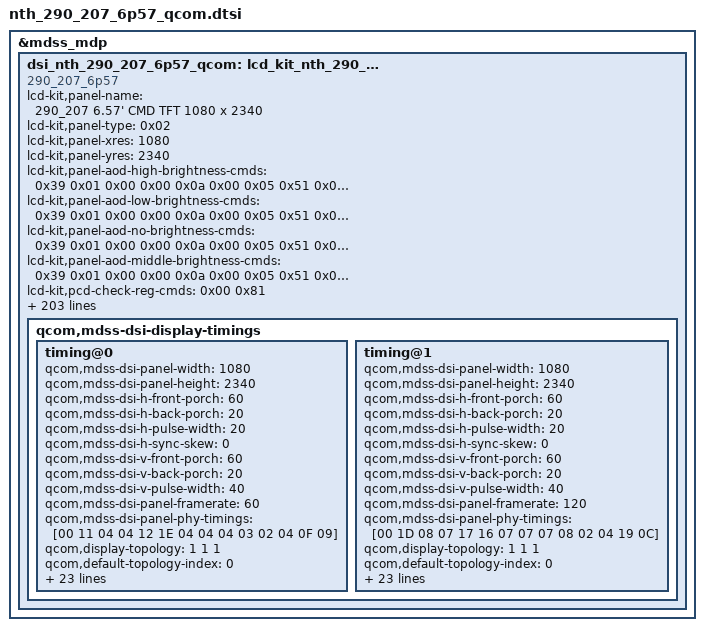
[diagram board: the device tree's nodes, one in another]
/* Copyright (c) 2013, The Linux Foundation. All rights reserved.
 *
 * This program is free software; you can redistribute it and/or modify
 * it under the terms of the GNU General Public License version 2 and
 * only version 2 as published by the Free Software Foundation.
 *
 * This program is distributed in the hope that it will be useful,
 * but WITHOUT ANY WARRANTY; without even the implied warranty of
 * MERCHANTABILITY or FITNESS FOR A PARTICULAR PURPOSE.  See the
 * GNU General Public License for more details.
 */

/*-------------------------------------------------------------------------
 * This file is autogenerated file using gcdb parser. Please do not edit it.
 * Update input XML file to add a new entry or update variable in this file
 * VERSION = 1.1
 *-----------------------------------------------------------------------*/
&mdss_mdp {
	dsi_nth_290_207_6p57_qcom: lcd_kit_nth_290_207_6p57_qcom {
		compatible = "290_207_6p57";
		lcd-kit,panel-name = "290_207 6.57' CMD TFT 1080 x 2340";
		lcd-kit,panel-type = <0x02>;
		lcd-kit,panel-xres = <1080>;
		lcd-kit,panel-yres = <2340>;
		lcd-kit,panel-aod-high-brightness-cmds = <0x39 0x01 0x00 0x00 0x0a 0x00 0x05 0x51 0x00 0x00 0x0F 0xFF>;
		lcd-kit,panel-aod-low-brightness-cmds = <0x39 0x01 0x00 0x00 0x0a 0x00 0x05 0x51 0x00 0x00 0x01 0x55>;
		lcd-kit,panel-aod-no-brightness-cmds = <0x39 0x01 0x00 0x00 0x0a 0x00 0x05 0x51 0x00 0x00 0x00 0x00>;
		lcd-kit,panel-aod-middle-brightness-cmds = <0x39 0x01 0x00 0x00 0x0a 0x00 0x05 0x51 0x00 0x00 0x07 0xFF>;
		lcd-kit,pcd-check-reg-cmds = <0x00 0x81>;
		lcd-kit,check-reg-on-cmds = <0x06 0x01 0x00 0x00 0x0a 0x00 0x01 0x0a>;
		lcd-kit,check-reg-on-value = <0x9c>;
		lcd-kit,check-aod-reg-on-cmds = <0x06 0x01 0x00 0x00 0x0a 0x00 0x01 0x0a>;
		lcd-kit,check-aod-reg-on-value = <0xdc>;
		lcd-kit,check-reg-off-cmds = <0x06 0x01 0x00 0x00 0x0a 0x00 0x01 0x0a>;
		lcd-kit,check-reg-off-value = <0x08>;
		lcd-kit,check-reg-on-cmds-state = "dsi_lp_mode";
		lcd-kit,check-aod-reg-on-cmds-state = "dsi_lp_mode";
		lcd-kit,check-reg-off-cmds-state = "dsi_lp_mode";
		lcd-kit,pcd-check-reg-value = <0x00 0x81>;
		lcd-kit,pcd-errflag-check-support = <0>;
		lcd-kit,checksum-enable-cmds = <0x39 0x01 0x00 0x00 0x14 0x00 0x05 0xFF 0xAA 0x55 0xA5 0x80
		0x15 0x01 0x00 0x00 0x0a 0x00 0x02 0xF2 0x03>;
		lcd-kit,checksum-enable-cmds-state = "dsi_lp_mode";
		lcd-kit,checksum-disable-cmds = <0x39 0x01 0x00 0x00 0x14 0x00 0x05 0xFF 0xAA 0x55 0xA5 0x80
		0x15 0x01 0x00 0x00 0x0a 0x00 0x02 0xF2 0x00>;
		lcd-kit,checksum-disable-cmds-state = "dsi_lp_mode";
		lcd-kit,checksum-cmds = <0x39 0x01 0x00 0x00 0x14 0x00 0x05 0xFF 0xAA 0x55 0xA5 0x80
		0x15 0x01 0x00 0x00 0x0a 0x00 0x02 0x6F 0x01
		0x14 0x01 0x00 0x00 0x0a 0x00 0x08 0xF2 0x00 0x00 0x00 0x00 0x00 0x00 0x00>;
		lcd-kit,checksum-cmds-state = "dsi_lp_mode";
		lcd-kit,checksum-value = <0x43 0xa5 0xba 0x9e 0xdf 0x7d 0x31 0xfb
		0xc5 0x11 0x12 0xec 0x22 0xed 0x74 0x12
		0x56 0x38 0xe1 0x0f 0xb2 0xaf 0xfe 0xce>;
		lcd-kit,hor-line-cmds = <0x39 0x01 0x00 0x00 0x00 0x00 0x06 0xF0 0x55 0xAA 0x52 0x08 0x01
		0x39 0x01 0x00 0x00 0x00 0x00 0x03 0xB0 0x0D 0x0D
		0x39 0x01 0x00 0x00 0x00 0x00 0x03 0xB3 0x23 0x23
		0x39 0x01 0x00 0x00 0x00 0x00 0x07 0xB7 0x1B 0x1B 0x1B 0x1B 0x1B 0x1B
		0x39 0x01 0x00 0x00 0x00 0x00 0x07 0xB7 0x5A 0x5A 0x5A 0x5A 0x5A 0x5A
		0x39 0x01 0x00 0x00 0x00 0x00 0x03 0xB1 0x0B 0x0B
		0x39 0x01 0x00 0x00 0x00 0x00 0x03 0xB4 0x23 0x23
		0x39 0x01 0x00 0x00 0x00 0x00 0x07 0xB8 0x46 0x46 0x46 0x46 0x46 0x46
		0x39 0x01 0x00 0x00 0x00 0x00 0x07 0xB8 0x7D 0x7D 0x7D 0x7D 0x7D 0x7D>;
		lcd-kit,hor-line-cmds-state = "dsi_lp_mode";
		lcd-kit,pcd-read-cmds = <0x05 0x01 0x00 0x00 0x14 0x00 0x01 0x28
		0x39 0x01 0x00 0x00 0x00 0x00 0x06 0xF0 0x55 0xAA 0x52 0x08 0x01
		0x39 0x01 0x00 0x00 0x00 0x00 0x05 0xD0 0x00 0x31 0x00 0x00
		0x15 0x01 0x00 0x00 0x00 0x00 0x02 0x6F 0x08
		0x15 0x01 0x00 0x00 0x78 0x00 0x02 0xD0 0x00
		0x39 0x01 0x00 0x00 0x00 0x00 0x06 0xF0 0x55 0xAA 0x52 0x08 0x01
		0x15 0x01 0x00 0x00 0x00 0x00 0x02 0x6F 0x02
		0x06 0x01 0x00 0x00 0x00 0x00 0x01 0xD0
		0x39 0x01 0x00 0x00 0x40 0x00 0x06 0xF0 0x55 0xAA 0x52 0x08 0x01
		0x39 0x01 0x00 0x00 0x00 0x00 0x05 0xD0 0x00 0x00 0x00 0x00
		0x15 0x01 0x00 0x00 0x00 0x00 0x02 0x6F 0x08
		0x15 0x01 0x00 0x00 0x00 0x00 0x02 0xD0 0x00
		0x05 0x01 0x00 0x00 0x4F 0x00 0x01 0x29>;
		lcd-kit,pcd-read-cmds-state  = "dsi_lp_mode";
		lcd-kit,vtc-line-cmds = <0x39 0x01 0x00 0x00 0x00 0x00 0x06 0xF0 0x55 0xAA 0x52 0x08 0x02
		0x15 0x01 0x00 0x00 0x00 0x00 0x02 0xCC 0x10
		0x39 0x01 0x00 0x00 0x00 0x00 0x06 0xF0 0x55 0xAA 0x52 0x08 0x02
		0x15 0x01 0x00 0x00 0x00 0x00 0x02 0xBF 0x18
		0x39 0x01 0x00 0x00 0x00 0x00 0x13 0xB0 0x00 0x00 0x00 0xBD 0x02 0x33 0x02 0x60 0x02 0x8B 0x02 0xEE 0x03 0x4D 0x03 0xA0 0x03 0xEC
		0x39 0x01 0x00 0x00 0x00 0x00 0x13 0xB1 0x04 0x31 0x04 0x70 0x04 0xDD 0x05 0x3E 0x05 0x95 0x05 0xE5 0x06 0x2E 0x06 0x76 0x06 0xF7
		0x39 0x01 0x00 0x00 0x00 0x00 0x0F 0xB2 0x07 0x69 0x07 0xD4 0x08 0xA1 0x09 0x61 0x0A 0x1D 0xFF 0xFF 0xFF 0xFF
		0x39 0x01 0x00 0x00 0x00 0x00 0x13 0xB3 0x00 0x00 0x00 0xB5 0x02 0x1D 0x02 0x3B 0x02 0x58 0x02 0x9E 0x02 0xE3 0x03 0x25 0x03 0x5F
		0x39 0x01 0x00 0x00 0x00 0x00 0x13 0xB4 0x03 0x96 0x03 0xC9 0x04 0x25 0x04 0x76 0x04 0xC1 0x05 0x05 0x05 0x46 0x05 0x81 0x05 0xEE
		0x39 0x01 0x00 0x00 0x00 0x00 0x0F 0xB5 0x06 0x51 0x06 0xAD 0x07 0x5A 0x07 0xFA 0x08 0x92 0xFF 0xFF 0xFF 0xFF
		0x39 0x01 0x00 0x00 0x00 0x00 0x13 0xB6 0x00 0x00 0x00 0xCE 0x02 0x68 0x02 0x9A 0x02 0xCA 0x03 0x37 0x03 0xA0 0x03 0xFF 0x04 0x4E
		0x39 0x01 0x00 0x00 0x00 0x00 0x13 0xB7 0x04 0x98 0x04 0xDB 0x05 0x54 0x05 0xBB 0x06 0x19 0x06 0x6D 0x06 0xBD 0x07 0x01 0x07 0x8C
		0x39 0x01 0x00 0x00 0x00 0x00 0x0F 0xB8 0x08 0x05 0x08 0x76 0x09 0x4E 0x0A 0x18 0x0A 0xE0 0xFF 0xFF 0xFF 0xFF>;
		lcd-kit,vtc-line-cmds-state  = "dsi_lp_mode";
		lcd-kit,ddic-lv-det-enter1-cmds = <0x39 0x01 0x00 0x00 0x0a 0x00 0x06 0xF0 0x55 0xAA 0x52 0x08 0x01
		0x15 0x01 0x00 0x00 0x14 0x00 0x02 0xC7 0xF8>;
		lcd-kit,ddic-lv-det-enter1-cmds-state  = "dsi_lp_mode";
		lcd-kit,ddic-lv-det-enter2-cmds = <0x39 0x01 0x00 0x00 0x0a 0x00 0x06 0xF0 0x55 0xAA 0x52 0x08 0x01
		0x15 0x01 0x00 0x00 0x14 0x00 0x02 0xC7 0xF8>;
		lcd-kit,ddic-lv-det-enter2-cmds-state  = "dsi_lp_mode";
		lcd-kit,ddic-lv-det-enter3-cmds = <0x39 0x01 0x00 0x00 0x0a 0x00 0x06 0xF0 0x55 0xAA 0x52 0x08 0x01
		0x15 0x01 0x00 0x00 0x14 0x00 0x02 0xC7 0xF8>;
		lcd-kit,ddic-lv-det-enter3-cmds-state  = "dsi_lp_mode";
		lcd-kit,ddic-lv-det-enter4-cmds = <0x39 0x01 0x00 0x00 0x0a 0x00 0x06 0xF0 0x55 0xAA 0x52 0x08 0x01
		0x15 0x01 0x00 0x00 0x14 0x00 0x02 0xC7 0xF8>;
		lcd-kit,ddic-lv-det-enter4-cmds-state  = "dsi_lp_mode";
		lcd-kit,ddic-lv-det-rd1-cmds = <0x06 0x01 0x00 0x00 0x0a 0x00 0x01 0x0a>;
		lcd-kit,ddic-lv-det-rd1-cmds-state  = "dsi_lp_mode";
		lcd-kit,ddic-lv-det-rd2-cmds = <0x06 0x01 0x00 0x00 0x0a 0x00 0x01 0x0a>;
		lcd-kit,ddic-lv-det-rd2-cmds-state  = "dsi_lp_mode";
		lcd-kit,ddic-lv-det-rd3-cmds = <0x06 0x01 0x00 0x00 0x0a 0x00 0x01 0x0a>;
		lcd-kit,ddic-lv-det-rd3-cmds-state  = "dsi_lp_mode";
		lcd-kit,ddic-lv-det-rd4-cmds = <0x06 0x01 0x00 0x00 0x0a 0x00 0x01 0x0a>;
		lcd-kit,ddic-lv-det-rd4-cmds-state  = "dsi_lp_mode";
		lcd-kit,ddic-lv-det-value1 = <0x9c>;
		lcd-kit,ddic-lv-det-value2 = <0x9c>;
		lcd-kit,ddic-lv-det-value3 = <0x9c>;
		lcd-kit,ddic-lv-det-value4 = <0x9c>;
		lcd-kit,ap-aod-support = <1>;
		lcd-kit,left-time-to-te-us = <28667>;
		lcd-kit,right-time-to-te-us = <29667>;
		lcd-kit,te-interval-time-us = <16667>;
		lcd-kit,check-reg-on-support = <0>;
		lcd-kit,check-reg-on-support-dsm-report = <0>;
		lcd-kit,check-aod-reg-on-support = <0>;
		lcd-kit,check-aod-reg-on-support-dsm-report = <0>;
		lcd-kit,check-reg-off-support = <0>;
		lcd-kit,check-reg-off-support-dsm-report = <0>;
		lcd-kit,checksum-support = <1>;
		lcd-kit,pcd-cmds-support = <1>;
		lcd-kit,pcd-check-reg-value-compare-mode = <3>;
		lcd-kit,vtc-line-support = <1>;
		lcd-kit,ddic-lv-det-support = <1>;
		lcd-kit,hor-line-support = <1>;
		lcd-kit,hor-line-duration = <600>;
		qcom,mdss-dsi-panel-type = "dsi_cmd_mode";
		qcom,mdss-pan-physical-width-dimension = <70>;
		qcom,mdss-pan-physical-height-dimension = <152>;
		qcom,dsi-ctrl-num = <0>;
		qcom,dsi-phy-num = <0>;
		qcom,panel-supply-entries = <&dsi_panel_pwr_supply>;
		qcom,mdss-dsi-virtual-channel-id = <0>;
		qcom,mdss-dsi-h-sync-pulse = <0>;
		qcom,mdss-dsi-bllp-eof-power-mode;
		qcom,mdss-dsi-bllp-power-mode;
		qcom,mdss-dsi-dma-schedule-line = <1>;
		qcom,mdss-dsi-bpp = <24>;
		qcom,mdss-dsi-color-order = "rgb_swap_rgb";
		qcom,mdss-dsi-underflow-color = <0xff>;
		qcom,mdss-dsi-border-color = <0>;
		qcom,mdss-dsi-traffic-mode = "burst_mode";
		qcom,mdss-dsi-lane-map = "lane_map_0123";
		qcom,mdss-dsi-lane-0-state;
		qcom,mdss-dsi-lane-1-state;
		qcom,mdss-dsi-lane-2-state;
		qcom,mdss-dsi-lane-3-state;
		qcom,mdss-dsi-mdp-trigger = "none";
		qcom,mdss-dsi-dma-trigger = "trigger_sw";
		qcom,mdss-dsi-te-pin-select = <1>;
		qcom,mdss-dsi-wr-mem-start = <0x2c>;
		qcom,mdss-dsi-wr-mem-continue = <0x3c>;
		qcom,mdss-dsi-te-dcs-command = <1>;
		qcom,mdss-dsi-te-check-enable;
		qcom,mdss-dsi-te-using-te-pin;
		qcom,dsi-panel-gpio-address = <0x0F100000 0x1000>;
		qcom,dsi-panel-gpio-pins = <12 44 80>;
		qcom,dsi-panel-gpio-names = "reg-gpio", "reset-gpio", "platform-te-gpio";
		qcom,mdss-dsi-t-clk-post = <0>;
		qcom,mdss-dsi-t-clk-pre = <0>;
		qcom,dsi-select-clocks = "mux_byte_clk0", "mux_pixel_clk0";
		qcom,mdss-dsi-stream = <0>;
		qcom,mdss-dsi-lp11-init;
		qcom,sublinks-count = <2>;
		qcom,lanes-per-sublink = <2>;
		qcom,mdss-dsi-panel-hdr-color-primaries = <14500 15500 32000 17000 15500 30000 8000 3000>;
		qcom,mdss-dsi-panel-peak-brightness = <4200000>;
		qcom,mdss-dsi-panel-blackness-level = <3230>;
		qcom,dynamic-mode-switch-enabled;
		qcom,dynamic-mode-switch-type = "dynamic-resolution-switch-immediate";
		qcom,mdss-dsi-bl-pmic-control-type = "bl_ctrl_dcs";
		qcom,mdss-dsi-bl-min-level = <1>;
		qcom,mdss-dsi-bl-max-level = <10000>;
		qcom,esd-check-enabled;
		qcom,mdss-dsi-panel-status-command = [06 01 00 00 00 00 02 AB 00
			39 01 00 00 00 00 05 FF AA 55 A5 81
			15 01 00 00 00 00 02 6F 0F
			06 01 00 00 00 00 01 FA
			06 01 00 00 00 00 01 0A
			06 01 00 00 00 00 02 91 00];
		qcom,mdss-dsi-panel-status-command-state = "dsi_lp_mode";
		qcom,mdss-dsi-panel-status-check-mode = "reg_read";
		qcom,mdss-dsi-panel-status-read-length = <2 0 0 1 1 2>;
		qcom,mdss-dsi-panel-status-value = <0x00 0x00>,<0x00>,<0x9C>,<0xAB 0x28>;
		lcd-kit,power-on-stage = <2 1 2
				9 1 1
				1 1 12
				5 1 5
				5 0 1
				5 1 15
				7 1 0
				6 1 0
				8 1 0>;
		lcd-kit,lp-on-stage = <0 0 0>;
		lcd-kit,lp-off-stage = <0 0 0>;
		lcd-kit,power-off-stage = <7 0 0
				6 0 0
				8 0 0
				5 0 1
				1 0 1
				9 0 2
				2 0 1>;
		lcd-kit,only-power-off-stage = <0 0 0>;
		lcd-kit,pt-support = <0>;
		lcd-kit,panel-on-always-reset = <0>;
		lcd-kit,lcd-vci = <1 13 3000000 3000000 3000000 10000 80>;
		lcd-kit,lcd-iovcc = <1 12 1800000 1800000 1800000 60700 80>;
		lcd-kit,lcd-vdd = <1 16 1200000 1200000 1200000 30000 80>;
		lcd-kit,lcd-reset = <2 44 0>;
		lcd-kit,lcd-vci-name = "vdd";
		lcd-kit,lcd-iovcc-name = "vddio";
		lcd-kit,lcd-vdd-name = "ddic";
		lcd-kit,project-id-support = <0>;
		lcd-kit,default-project-id = "G21579250";
		lcd-kit,sn-code-support = <1>;
		lcd-kit,oem-info-support = <1>;
		lcd-kit,oem-barcode-2d-support = <1>;
		lcd-kit,oem-barcode-2d-num-offset = <0>;
		lcd-kit,barcode-2d-cmds = <0x39 0x01 0x00 0x00 0x0a 0x00 0x06 0xF0 0x55 0xAA 0x52 0x08 0x03
                  0x14 0x01 0x00 0x00 0x0a 0x00 0x15 0xDF 0x00 0x00 0x00 0x00 0x00 0x00 0x00 0x00 0x00 0x00 0x00 0x00 0x00 0x00 0x00 0x00 0x00 0x00 0x00 0x00>;
		lcd-kit,barcode-2d-cmds-state = "dsi_lp_mode";
		lcd-kit,panel-getblmaxnit-type = <0>;
		lcd-kit,panel-blmaxnit-min-value = <400>;
		lcd-kit,inversion-support = <0>;
		lcd-kit,panel-gpio-offset = <336>;
		lcd-kit,finger-unlock-state-support = <0>;
		lcd-kit,finger-handle-esd-support = <1>;
		lcd-kit,panel-bl-max-nit = <450>;
		lcd-kit,panel-bl-min = <3>;
		lcd-kit,panel-bl-max = <10000>;
		lcd-kit,panel-bl-def = <2047>;
		lcd-kit,check-reg-support = <0>;
		lcd-kit,thp-proximity-support = <0>;
		lcd-kit,proximity-reset-delay-min = <65>;
		lcd-kit,backlight-cmds = <0x39 0x01 0x00 0x00 0x00 0x00 0x03 0x51 0x00 0x00>;
		lcd-kit,backlight-cmds-state = "dsi_lp_mode";
		lcd-kit,backlight-order = <0>;
		lcd-kit,backlight-need-sync = <0>;
		lcd-kit,fps-support = <1>;
		lcd-kit,default-fps = <60>;
		lcd-kit,panel-support-fps-list = <60 120>;
		qcom,mdss-dsi-display-timings {
			timing@0 {
				qcom,mdss-dsi-panel-width = <1080>;
				qcom,mdss-dsi-panel-height = <2340>;
				qcom,mdss-dsi-h-front-porch = <60>;
				qcom,mdss-dsi-h-back-porch = <20>;
				qcom,mdss-dsi-h-pulse-width = <20>;
				qcom,mdss-dsi-h-sync-skew = <0>;
				qcom,mdss-dsi-v-front-porch = <60>;
				qcom,mdss-dsi-v-back-porch = <20>;
				qcom,mdss-dsi-v-pulse-width = <40>;
				qcom,mdss-dsi-panel-framerate = <60>;
				qcom,mdss-dsi-panel-phy-timings= [00 11 04 04 12 1E 04
			04 04 03 02 04 0F 09];
				qcom,display-topology  = <1 1 1>;
				qcom,default-topology-index  = <0>;
				qcom,mdss-dsi-on-command = [39 01 00 00 00 00 05 3B 00 10 00 14
		15 01 00 00 00 00 02 03 01
		15 01 00 00 00 00 02 90 01
		39 01 00 00 00 00 13 91 AB 28 00 3C C2 00 03 1C 07 D0 00 0F 01 A1 00 D9 10 F0
		05 01 00 00 00 00 01 2C
		15 01 00 00 00 00 02 53 20
		05 01 00 00 00 00 01 35
		39 01 00 00 00 00 05 2A 00 00 04 37
		39 01 00 00 00 00 05 2B 00 00 09 23
		39 01 00 00 0a 00 06 F0 55 AA 52 08 01
		15 01 00 00 00 00 02 C7 F8
		05 01 00 00 78 00 01 11
		15 01 00 00 09 00 02 2F 01
		05 01 00 00 2a 00 01 29];
				qcom,mdss-dsi-on-command-state = "dsi_lp_mode";
				qcom,mdss-dsi-off-command = [05 01 00 00 0a 00 01 28
			05 01 00 00 46 00 01 10];
				qcom,mdss-dsi-off-command-state = "dsi_lp_mode";
				qcom,compression-mode = "dsc";
				qcom,mdss-dsc-slice-height = <60>;
				qcom,mdss-dsc-slice-width = <1080>;
				qcom,mdss-dsc-slice-per-pkt = <1>;
				qcom,mdss-dsc-bit-per-component = <10>;
				qcom,mdss-dsc-bit-per-pixel = <8>;
				qcom,mdss-dsc-block-prediction-enable;
				qcom,mdss-dsi-timing-switch-command = [15 01 00 00 16 00 02 2F 01];
				qcom,mdss-dsi-timing-switch-command-state = "dsi_lp_mode";
				qcom,mdss-dsi-lp1-command = [39 01 00 00 00 00 06 F0 55 AA 52 08 00
		15 01 00 00 00 00 02 65 01
		15 01 00 00 00 00 02 B2 08
		15 01 00 00 00 00 02 2F 01
		05 01 00 00 00 00 01 39
		05 01 00 00 00 00 01 2C];
				qcom,mdss-dsi-lp1-command-state = "dsi_lp_mode";
				qcom,mdss-dsi-nolp-command = [39 01 00 00 00 00 06 F0 55 AA 52 08 00
		15 01 00 00 00 00 02 65 00
		15 01 00 00 00 00 02 B2 18
		05 01 00 00 00 00 01 38
		05 01 00 00 00 00 01 2C
		15 01 00 00 00 00 02 2F 01];
				qcom,mdss-dsi-nolp-command-state = "dsi_lp_mode";
			};
			timing@1 {
				qcom,mdss-dsi-panel-width = <1080>;
				qcom,mdss-dsi-panel-height = <2340>;
				qcom,mdss-dsi-h-front-porch = <60>;
				qcom,mdss-dsi-h-back-porch = <20>;
				qcom,mdss-dsi-h-pulse-width = <20>;
				qcom,mdss-dsi-h-sync-skew = <0>;
				qcom,mdss-dsi-v-front-porch = <60>;
				qcom,mdss-dsi-v-back-porch = <20>;
				qcom,mdss-dsi-v-pulse-width = <40>;
				qcom,mdss-dsi-panel-framerate = <120>;
				qcom,mdss-dsi-panel-phy-timings= [00 1D 08 07 17 16 07
			07 07 08 02 04 19 0C];
				qcom,display-topology  = <1 1 1>;
				qcom,default-topology-index  = <0>;
				qcom,mdss-dsi-on-command = [39 01 00 00 00 00 05 3B 00 10 00 14
		15 01 00 00 00 00 02 03 01
		15 01 00 00 00 00 02 90 01
		39 01 00 00 00 00 13 91 AB 28 00 3C C2 00 03 1C 07 D0 00 0F 01 A1 00 D9 10 F0
		05 01 00 00 00 00 01 2C
		15 01 00 00 00 00 02 53 20
		05 01 00 00 00 00 01 35
		39 01 00 00 00 00 05 2A 00 00 04 37
		39 01 00 00 00 00 05 2B 00 00 09 23
		39 01 00 00 0a 00 06 F0 55 AA 52 08 01
		15 01 00 00 00 00 02 C7 F8
		05 01 00 00 78 00 01 11
		15 01 00 00 0a 00 02 2F 02
		05 01 00 00 2a 00 01 29];
				qcom,mdss-dsi-on-command-state = "dsi_lp_mode";
				qcom,mdss-dsi-off-command = [05 01 00 00 14 00 01 28
		05 01 00 00 78 00 01 10];
				qcom,mdss-dsi-off-command-state = "dsi_lp_mode";
				qcom,compression-mode = "dsc";
				qcom,mdss-dsc-slice-height = <60>;
				qcom,mdss-dsc-slice-width = <1080>;
				qcom,mdss-dsc-slice-per-pkt = <1>;
				qcom,mdss-dsc-bit-per-component = <10>;
				qcom,mdss-dsc-bit-per-pixel = <8>;
				qcom,mdss-dsc-block-prediction-enable;
				qcom,mdss-dsi-timing-switch-command = [15 01 00 00 0a 00 02 2F 02];
				qcom,mdss-dsi-timing-switch-command-state = "dsi_lp_mode";
				qcom,mdss-dsi-lp1-command = [39 01 00 00 00 00 06 F0 55 AA 52 08 00
		15 01 00 00 00 00 02 65 01
		15 01 00 00 00 00 02 B2 08
		15 01 00 00 00 00 02 2F 01
		05 01 00 00 00 00 01 39
		05 01 00 00 00 00 01 2C];
				qcom,mdss-dsi-lp1-command-state = "dsi_lp_mode";
				qcom,mdss-dsi-nolp-command = [39 01 00 00 00 00 06 F0 55 AA 52 08 00
		15 01 00 00 00 00 02 65 00
		15 01 00 00 00 00 02 B2 18
		05 01 00 00 00 00 01 38
		15 01 00 00 00 00 02 2F 02
		05 01 00 00 00 00 01 2C];
				qcom,mdss-dsi-nolp-command-state = "dsi_lp_mode";
			};
		};
    };
};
